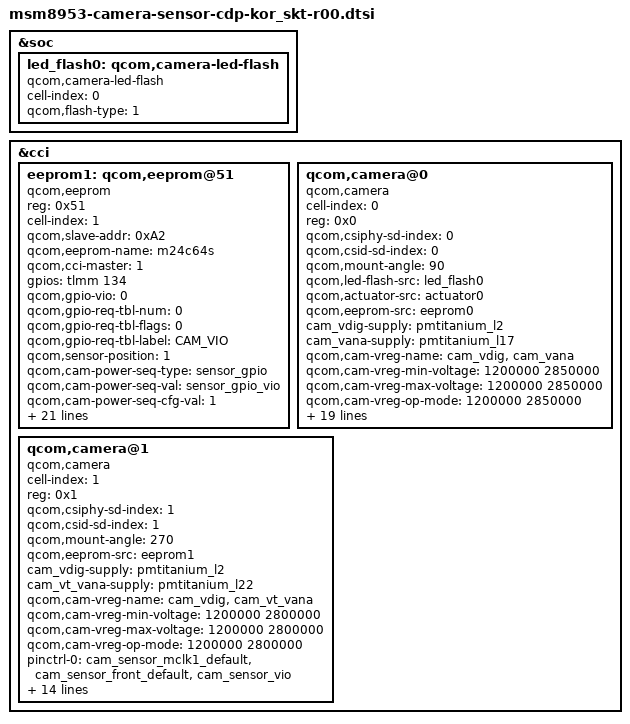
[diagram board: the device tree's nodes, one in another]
/*
 * Copyright (c) 2015, The Linux Foundation. All rights reserved.
 *
 * This program is free software; you can redistribute it and/or modify
 * it under the terms of the GNU General Public License version 2 and
 * only version 2 as published by the Free Software Foundation.
 *
 * This program is distributed in the hope that it will be useful,
 * but WITHOUT ANY WARRANTY; without even the implied warranty of
 * MERCHANTABILITY or FITNESS FOR A PARTICULAR PURPOSE.  See the
 * GNU General Public License for more details.
 */

&soc {

        led_flash0: qcom,camera-led-flash {
		cell-index = <0>;
                compatible = "qcom,camera-led-flash";
                qcom,flash-type = <1>;
	};

};

&cci {
	eeprom1: qcom,eeprom@51 {
		compatible = "qcom,eeprom";
		reg = <0x51>;
		cell-index = <1>;
		qcom,slave-addr = <0xA2>;
		qcom,eeprom-name = "m24c64s";
		qcom,cci-master = <1>;
		gpios = <&tlmm 134 0>;
		qcom,gpio-vio = <0>;
		qcom,gpio-req-tbl-num = <0>;
		qcom,gpio-req-tbl-flags = <0>;
		qcom,gpio-req-tbl-label = "CAM_VIO";
		qcom,sensor-position = <1>;
		qcom,cam-power-seq-type = "sensor_gpio";
		qcom,cam-power-seq-val = "sensor_gpio_vio";
		qcom,cam-power-seq-cfg-val = <1>;
		qcom,cam-power-seq-delay = <1>;

		qcom,num-blocks = <6>;
		qcom,page0 = <0 0x0 0 0x0 0 0>;
		qcom,poll0 = <0 0x0 0 0x0 0 0>;
		qcom,mem0 = <0x60 0x0 2 0 1 0>;
		qcom,page1 = <0 0x0 0 0x0 0 0>;
		qcom,poll1 = <0 0x0 0 0x0 0 0>;
		qcom,mem1 = <4 0xFC 2 0 1 0>;
		qcom,page2 = <0 0x0 0 0x0 0 0>;
		qcom,poll2 = <0 0x0 0 0x0 0 0>;
		qcom,mem2 = <0x20 0x200 2 0 1 0>;
		qcom,page3 = <0 0x0 0 0x0 0 0>;
		qcom,poll3 = <0 0x0 0 0x0 0 0>;
		qcom,mem3 = <4 0x2FC 2 0 1 0>;
		qcom,page4 = <0 0x0 0 0x0 0 0>;
		qcom,poll4 = <0 0x0 0 0x0 0 0>;
		qcom,mem4 = <0x700 0x300 2 0 1 0>;
		qcom,page5 = <0 0x0 0 0x0 0 0>;
		qcom,poll5 = <0 0x0 0 0x0 0 0>;
		qcom,mem5 = <4 0xAFC 2 0 1 0>;
		qcom,total-size = <0xB00>;
    };

	qcom,camera@0 {
		cell-index = <0>;
		compatible = "qcom,camera";
		reg = <0x0>;
		qcom,csiphy-sd-index = <0>;
		qcom,csid-sd-index = <0>;
		qcom,mount-angle = <90>;
		qcom,led-flash-src = <&led_flash0>;		
		qcom,actuator-src = <&actuator0>;
		qcom,eeprom-src = <&eeprom0>;
		cam_vdig-supply = <&pmtitanium_l2>;
		cam_vana-supply = <&pmtitanium_l17>;
		qcom,cam-vreg-name = "cam_vdig","cam_vana";
		qcom,cam-vreg-min-voltage = <1200000 2850000>;
		qcom,cam-vreg-max-voltage = <1200000 2850000>;
		qcom,cam-vreg-op-mode = <1200000 2850000>;
		pinctrl-names = "cam_default", "cam_suspend";
		pinctrl-0 = <&cam_sensor_mclk0_default
				&cam_sensor_rear_default &cam_sensor_vio &cam_sensor_vaf>;
		pinctrl-1 = <&cam_sensor_mclk0_sleep &cam_sensor_rear_sleep &cam_sensor_vio_sleep &cam_sensor_vaf_sleep>;
		gpios = <&tlmm 26 0>,
			<&tlmm 40 0>,
			<&tlmm 134 0>,
			<&tlmm 46 0>;
		qcom,gpio-reset = <1>;
		qcom,gpio-vio = <2>;
		qcom,gpio-vaf = <3>;
		qcom,gpio-req-tbl-num = <0 1 2 3>;
		qcom,gpio-req-tbl-flags = <1 0 0 0>;
		qcom,gpio-req-tbl-label = "CAMIF_MCLK0",
			"CAM_RESET0",
			"CAM_VIO_EN",
			"CAM_VAF_EN";
		qcom,sensor-position = <0>;
		qcom,sensor-mode = <0>;
		qcom,cci-master = <0>;
		status = "ok";
		clocks = <&clock_gcc clk_mclk0_clk_src>,
				<&clock_gcc clk_gcc_camss_mclk0_clk>;
		clock-names = "cam_src_clk", "cam_clk";
	};

	qcom,camera@1 {
		cell-index = <1>;
		compatible = "qcom,camera";
		reg = <0x1>;
		qcom,csiphy-sd-index = <1>;
		qcom,csid-sd-index = <1>;
		qcom,mount-angle = <270>;
		qcom,eeprom-src = <&eeprom1>;
		cam_vdig-supply = <&pmtitanium_l2>;
		cam_vt_vana-supply = <&pmtitanium_l22>;
		qcom,cam-vreg-name = "cam_vdig","cam_vt_vana";
		qcom,cam-vreg-min-voltage = <1200000 2800000>;
		qcom,cam-vreg-max-voltage = <1200000 2800000>;
		qcom,cam-vreg-op-mode = <1200000 2800000>;
		pinctrl-names = "cam_default", "cam_suspend";
		pinctrl-0 = <&cam_sensor_mclk1_default &cam_sensor_front_default &cam_sensor_vio>;
		pinctrl-1 = <&cam_sensor_mclk1_sleep &cam_sensor_front_sleep &cam_sensor_vio_sleep>;
		gpios = <&tlmm 27 0>,
			<&tlmm 129 0>,
			<&tlmm 134 0>;
		qcom,gpio-reset = <1>;
		qcom,gpio-vio = <2>;
		qcom,gpio-req-tbl-num = <0 1 2>;
		qcom,gpio-req-tbl-flags = <1 0 0>;
		qcom,gpio-req-tbl-label = "CAMIF_MCLK1",
			"CAM_RESET1",
    		"CAM_VIO_EN";
		qcom,sensor-position = <1>;
		qcom,sensor-mode = <0>;
		qcom,cci-master = <0>;
		status = "ok";
		clocks = <&clock_gcc clk_mclk1_clk_src>,
				<&clock_gcc clk_gcc_camss_mclk1_clk>;
		clock-names = "cam_src_clk", "cam_clk";
	};
	/*qcom,camera@2 {
		cell-index = <2>;
		compatible = "qcom,camera";
		reg = <0x02>;
		qcom,csiphy-sd-index = <1>;
		qcom,csid-sd-index = <1>;
		qcom,mount-angle = <90>;
		cam_vdig-supply = <&pm8950_l23>;
		cam_vana-supply = <&pm8950_l22>;
		cam_vio-supply = <&pm8950_l6>;
		cam_vaf-supply = <&pm8950_l17>;
		qcom,cam-vreg-name = "cam_vdig", "cam_vio", "cam_vana",
							"cam_vaf";
		qcom,cam-vreg-min-voltage = <1200000 0 2800000 2850000>;
		qcom,cam-vreg-max-voltage = <1200000 0 2800000 2850000>;
		qcom,cam-vreg-op-mode = <105000 0 80000 100000>;
		qcom,gpio-no-mux = <0>;
		pinctrl-names = "cam_default", "cam_suspend";
		pinctrl-0 = <&cam_sensor_mclk2_default &cam_sensor_front1_default>;
		pinctrl-1 = <&cam_sensor_mclk2_sleep &cam_sensor_front1_sleep>;
		gpios = <&tlmm 28 0>,
			<&tlmm 40 0>,
			<&tlmm 39 0>;
		qcom,gpio-reset = <1>;
		qcom,gpio-standby = <2>;
		qcom,gpio-req-tbl-num = <0 1 2>;
		qcom,gpio-req-tbl-flags = <1 0 0>;
		qcom,gpio-req-tbl-label = "CAMIF_MCLK2",
					  "CAM_RESET2",
					  "CAM_STANDBY2";
		qcom,sensor-position = <1>;
		qcom,sensor-mode = <0>;
		qcom,cci-master = <0>;
		status = "ok";
		clocks = <&clock_gcc clk_mclk2_clk_src>,
			<&clock_gcc clk_gcc_camss_mclk2_clk>;
		clock-names = "cam_src_clk", "cam_clk";
	};*/
};
